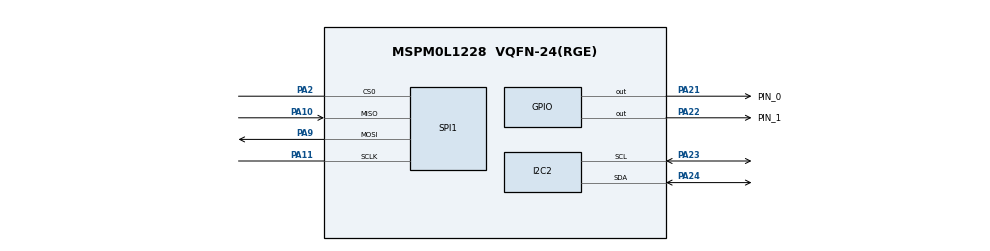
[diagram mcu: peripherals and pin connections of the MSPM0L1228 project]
/**
 * These arguments were used when this file was generated. They will be automatically applied on subsequent loads
 * via the GUI or CLI. Run CLI with '--help' for additional information on how to override these arguments.
 * @cliArgs --device "MSPM0L122X" --part "Default" --package "VQFN-24(RGE)" --product "mspm0_sdk@2.10.00.04"
 * @v2CliArgs --device "MSPM0L1228" --package "VQFN-24(RGE)" --product "mspm0_sdk@2.10.00.04"
 * @versions {"tool":"1.26.2+4477"}
 */

/**
 * Import the modules used in this configuration.
 */
const GPIO   = scripting.addModule("/ti/driverlib/GPIO", {}, false);
const GPIO1  = GPIO.addInstance();
const GPIO2  = GPIO.addInstance();
const I2C    = scripting.addModule("/ti/driverlib/I2C", {}, false);
const I2C1   = I2C.addInstance();
const I2C2   = I2C.addInstance();
const SPI    = scripting.addModule("/ti/driverlib/SPI", {}, false);
const SPI1   = SPI.addInstance();
const SPI2   = SPI.addInstance();
const SYSCTL = scripting.addModule("/ti/driverlib/SYSCTL");
const UART   = scripting.addModule("/ti/driverlib/UART", {}, false);
const UART1  = UART.addInstance();

/**
 * Write custom configuration values to the imported modules.
 */
GPIO1.$name                         = "GPIO_GRP_0";
GPIO1.associatedPins[0].$name       = "PIN_0";
GPIO1.associatedPins[0].pin.$assign = "PA21";

const Board = scripting.addModule("/ti/driverlib/Board", {}, false);

GPIO2.$name                         = "GPIO_GRP_1";
GPIO2.associatedPins[0].$name       = "PIN_1";
GPIO2.associatedPins[0].pin.$assign = "PA22";

I2C1.$name              = "I2C_0";
I2C1.peripheral.$assign = "I2C0";
I2C1.sdaPinConfig.$name = "ti_driverlib_gpio_GPIOPinGeneric0";
I2C1.sclPinConfig.$name = "ti_driverlib_gpio_GPIOPinGeneric1";

I2C2.$name                             = "I2C_2";
I2C2.peripheral.$assign                = "I2C2";
I2C2.peripheral.sdaPin.$assign         = "PA24";
I2C2.peripheral.sclPin.$assign         = "PA23";
I2C2.sdaPinConfig.hideOutputInversion  = scripting.forceWrite(false);
I2C2.sdaPinConfig.onlyInternalResistor = scripting.forceWrite(false);
I2C2.sdaPinConfig.passedPeripheralType = scripting.forceWrite("Digital");
I2C2.sdaPinConfig.$name                = "ti_driverlib_gpio_GPIOPinGeneric8";
I2C2.sclPinConfig.hideOutputInversion  = scripting.forceWrite(false);
I2C2.sclPinConfig.onlyInternalResistor = scripting.forceWrite(false);
I2C2.sclPinConfig.passedPeripheralType = scripting.forceWrite("Digital");
I2C2.sclPinConfig.$name                = "ti_driverlib_gpio_GPIOPinGeneric9";

SPI1.$name                      = "SPI_0";
SPI1.peripheral.sclkPin.$assign = "PA11";
SPI1.peripheral.mosiPin.$assign = "PA9";
SPI1.peripheral.misoPin.$assign = "PA10";
SPI1.peripheral.cs0Pin.$assign  = "PA2";
SPI1.sclkPinConfig.$name        = "ti_driverlib_gpio_GPIOPinGeneric3";
SPI1.mosiPinConfig.$name        = "ti_driverlib_gpio_GPIOPinGeneric4";
SPI1.misoPinConfig.$name        = "ti_driverlib_gpio_GPIOPinGeneric5";
SPI1.cs0PinConfig.$name         = "ti_driverlib_gpio_GPIOPinGeneric12";

SPI2.$name               = "SPI_1";
SPI2.sclkPinConfig.$name = "ti_driverlib_gpio_GPIOPinGeneric2";
SPI2.mosiPinConfig.$name = "ti_driverlib_gpio_GPIOPinGeneric6";
SPI2.misoPinConfig.$name = "ti_driverlib_gpio_GPIOPinGeneric7";
SPI2.cs0PinConfig.$name  = "ti_driverlib_gpio_GPIOPinGeneric13";

SYSCTL.clockTreeEn = true;

UART1.$name             = "UART_0";
UART1.txPinConfig.$name = "ti_driverlib_gpio_GPIOPinGeneric10";
UART1.rxPinConfig.$name = "ti_driverlib_gpio_GPIOPinGeneric11";

const ProjectConfig              = scripting.addModule("/ti/project_config/ProjectConfig", {}, false);
ProjectConfig.migrationCondition = true;

/**
 * Pinmux solution for unlocked pins/peripherals. This ensures that minor changes to the automatic solver in a future
 * version of the tool will not impact the pinmux you originally saw.  These lines can be completely deleted in order to
 * re-solve from scratch.
 */
Board.peripheral.$suggestSolution          = "DEBUGSS";
Board.peripheral.swclkPin.$suggestSolution = "PA20";
Board.peripheral.swdioPin.$suggestSolution = "PA19";
I2C1.peripheral.sdaPin.$suggestSolution    = "PA0";
I2C1.peripheral.sclPin.$suggestSolution    = "PA1";
SPI1.peripheral.$suggestSolution           = "SPI0";
SPI2.peripheral.$suggestSolution           = "SPI1";
SPI2.peripheral.sclkPin.$suggestSolution   = "PA17";
SPI2.peripheral.mosiPin.$suggestSolution   = "PA18";
SPI2.peripheral.misoPin.$suggestSolution   = "PA16";
SPI2.peripheral.cs0Pin.$suggestSolution    = "PA26";
UART1.peripheral.$suggestSolution          = "UART1";
UART1.peripheral.rxPin.$suggestSolution    = "PA4";
UART1.peripheral.txPin.$suggestSolution    = "PA3";
